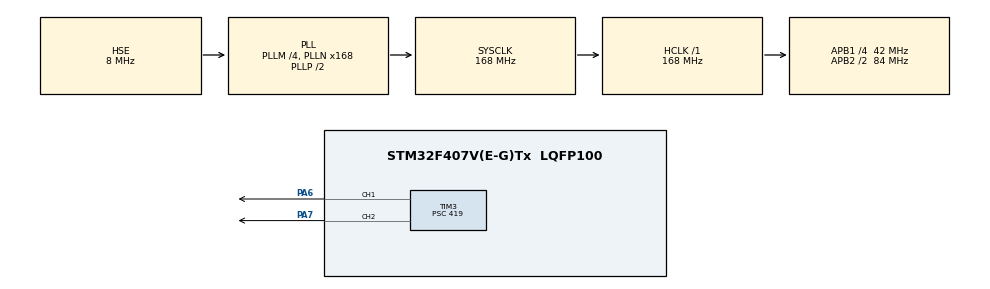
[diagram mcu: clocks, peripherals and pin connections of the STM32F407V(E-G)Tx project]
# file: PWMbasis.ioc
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Mcu.Family=STM32F4
Mcu.Name=STM32F407V(E-G)Tx
Mcu.Package=LQFP100
NVIC.PriorityGroup=NVIC_PRIORITYGROUP_4
PA13.Mode=Serial_Wire
PA13.Signal=SYS_JTMS-SWDIO
PA14.Mode=Serial_Wire
PA14.Signal=SYS_JTCK-SWCLK
PA6.Signal=S_TIM3_CH1
PA7.Signal=S_TIM3_CH2
PH0-OSC_IN.Mode=HSE-External-Oscillator
PH0-OSC_IN.Signal=RCC_OSC_IN
PH1-OSC_OUT.Mode=HSE-External-Oscillator
PH1-OSC_OUT.Signal=RCC_OSC_OUT
ProjectManager.HeapSize=0x200
ProjectManager.StackSize=0x400
ProjectManager.TargetToolchain=STM32CubeIDE
RCC.48MHZClocksFreq_Value=84000000
RCC.AHBFreq_Value=168000000
RCC.APB1CLKDivider=RCC_HCLK_DIV4
RCC.APB1Freq_Value=42000000
RCC.APB1TimFreq_Value=84000000
RCC.APB2CLKDivider=RCC_HCLK_DIV2
RCC.APB2Freq_Value=84000000
RCC.APB2TimFreq_Value=168000000
RCC.CortexFreq_Value=168000000
RCC.HCLKFreq_Value=168000000
RCC.HSE_VALUE=8000000
RCC.HSI_VALUE=16000000
RCC.LSE_VALUE=32768
RCC.PLLM=4
RCC.PLLN=168
RCC.PLLSourceVirtual=RCC_PLLSOURCE_HSE
RCC.SYSCLKFreq_VALUE=168000000
RCC.SYSCLKSource=RCC_SYSCLKSOURCE_PLLCLK
RCC.VCOOutputFreq_Value=336000000
SH.S_TIM3_CH1.0=TIM3_CH1,PWM Generation1 CH1
SH.S_TIM3_CH2.0=TIM3_CH2,PWM Generation2 CH2
TIM3.Channel-PWM\ Generation1\ CH1=TIM_CHANNEL_1
TIM3.Channel-PWM\ Generation2\ CH2=TIM_CHANNEL_2
TIM3.OCMode_PWM-PWM\ Generation1\ CH1=TIM_OCMODE_PWM2
TIM3.OCMode_PWM-PWM\ Generation2\ CH2=TIM_OCMODE_PWM2
TIM3.Prescaler=419
board=custom

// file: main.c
/* USER CODE BEGIN Header */
/**
  ******************************************************************************
  * @file           : main.c
  * @brief          : Main program body
  ******************************************************************************
  * @attention
  *
  * Copyright (c) 2024 STMicroelectronics.
  * All rights reserved.
  *
  * This software is licensed under terms that can be found in the LICENSE file
  * in the root directory of this software component.
  * If no LICENSE file comes with this software, it is provided AS-IS.
  *
  ******************************************************************************
  */
/* USER CODE END Header */
#include "main.h"

TIM_HandleTypeDef htim3;

void SystemClock_Config(void);
static void MX_GPIO_Init(void);
static void MX_TIM3_Init(void);

int main(void)
{

  /* MCU Configuration--------------------------------------------------------*/

  /* Reset of all peripherals, Initializes the Flash interface and the Systick. */
  HAL_Init();

  /* Configure the system clock */
  SystemClock_Config();

  /* Initialize all configured peripherals */
  MX_GPIO_Init();
  MX_TIM3_Init();
  /* USER CODE BEGIN 2 */
  HAL_TIM_PWM_Start(&htim3, TIM_CHANNEL_1); //LED D2 Start timer 3 channel 1
  HAL_TIM_PWM_Start(&htim3, TIM_CHANNEL_2); //LED D2 Start timer 3 channel 1
  __HAL_TIM_SET_AUTORELOAD(&htim3,2000);  //set the pwm freq to 50hz (42Mhz/420)/2000
  /* USER CODE END 2 */

  /* Infinite loop */
  while (1)
  {

    /* USER CODE BEGIN 3 */
	  __HAL_TIM_SET_COMPARE(&htim3, TIM_CHANNEL_1, 200); //LED D2 Set 10% from ARR (2000)

	  HAL_Delay(2000);

	  __HAL_TIM_SET_COMPARE(&htim3, TIM_CHANNEL_1, 600); //LED D2 Set 30% from ARR (2000)

	  HAL_Delay(2000);

	  __HAL_TIM_SET_COMPARE(&htim3, TIM_CHANNEL_1, 1200); //LED D2 Set 60% from ARR (2000)

	  HAL_Delay(2000);

	  __HAL_TIM_SET_COMPARE(&htim3, TIM_CHANNEL_2, 100); //LED D3 Set 5%  from ARR (2000)

	  HAL_Delay(2000);

	  __HAL_TIM_SET_COMPARE(&htim3, TIM_CHANNEL_2, 300); //LED D3 Set 15% from ARR (2000)

	  HAL_Delay(2000);

	  __HAL_TIM_SET_COMPARE(&htim3, TIM_CHANNEL_2, 0); //LED D3 stop

	  HAL_Delay(2000);
  }
  /* USER CODE END 3 */
}

void SystemClock_Config(void)
{
  RCC_OscInitTypeDef RCC_OscInitStruct = {0};
  RCC_ClkInitTypeDef RCC_ClkInitStruct = {0};

  /** Configure the main internal regulator output voltage
  */
  __HAL_RCC_PWR_CLK_ENABLE();
  __HAL_PWR_VOLTAGESCALING_CONFIG(PWR_REGULATOR_VOLTAGE_SCALE1);

  /** Initializes the RCC Oscillators according to the specified parameters
  * in the RCC_OscInitTypeDef structure.
  */
  RCC_OscInitStruct.OscillatorType = RCC_OSCILLATORTYPE_HSE;
  RCC_OscInitStruct.HSEState = RCC_HSE_ON;
  RCC_OscInitStruct.PLL.PLLState = RCC_PLL_ON;
  RCC_OscInitStruct.PLL.PLLSource = RCC_PLLSOURCE_HSE;
  RCC_OscInitStruct.PLL.PLLM = 4;
  RCC_OscInitStruct.PLL.PLLN = 168;
  RCC_OscInitStruct.PLL.PLLP = RCC_PLLP_DIV2;
  RCC_OscInitStruct.PLL.PLLQ = 4;
  if (HAL_RCC_OscConfig(&RCC_OscInitStruct) != HAL_OK)
  {
    Error_Handler();
  }

  /** Initializes the CPU, AHB and APB buses clocks
  */
  RCC_ClkInitStruct.ClockType = RCC_CLOCKTYPE_HCLK|RCC_CLOCKTYPE_SYSCLK
                              |RCC_CLOCKTYPE_PCLK1|RCC_CLOCKTYPE_PCLK2;
  RCC_ClkInitStruct.SYSCLKSource = RCC_SYSCLKSOURCE_PLLCLK;
  RCC_ClkInitStruct.AHBCLKDivider = RCC_SYSCLK_DIV1;
  RCC_ClkInitStruct.APB1CLKDivider = RCC_HCLK_DIV4;
  RCC_ClkInitStruct.APB2CLKDivider = RCC_HCLK_DIV2;

  if (HAL_RCC_ClockConfig(&RCC_ClkInitStruct, FLASH_LATENCY_5) != HAL_OK)
  {
    Error_Handler();
  }
}

static void MX_TIM3_Init(void)
{

  TIM_MasterConfigTypeDef sMasterConfig = {0};
  TIM_OC_InitTypeDef sConfigOC = {0};

  htim3.Instance = TIM3;
  htim3.Init.Prescaler = 419;
  htim3.Init.CounterMode = TIM_COUNTERMODE_UP;
  htim3.Init.Period = 65535;
  htim3.Init.ClockDivision = TIM_CLOCKDIVISION_DIV1;
  htim3.Init.AutoReloadPreload = TIM_AUTORELOAD_PRELOAD_DISABLE;
  if (HAL_TIM_PWM_Init(&htim3) != HAL_OK)
  {
    Error_Handler();
  }
  sMasterConfig.MasterOutputTrigger = TIM_TRGO_RESET;
  sMasterConfig.MasterSlaveMode = TIM_MASTERSLAVEMODE_DISABLE;
  if (HAL_TIMEx_MasterConfigSynchronization(&htim3, &sMasterConfig) != HAL_OK)
  {
    Error_Handler();
  }
  sConfigOC.OCMode = TIM_OCMODE_PWM2;
  sConfigOC.Pulse = 0;
  sConfigOC.OCPolarity = TIM_OCPOLARITY_HIGH;
  sConfigOC.OCFastMode = TIM_OCFAST_DISABLE;
  if (HAL_TIM_PWM_ConfigChannel(&htim3, &sConfigOC, TIM_CHANNEL_1) != HAL_OK)
  {
    Error_Handler();
  }
  if (HAL_TIM_PWM_ConfigChannel(&htim3, &sConfigOC, TIM_CHANNEL_2) != HAL_OK)
  {
    Error_Handler();
  }
  HAL_TIM_MspPostInit(&htim3);

}

static void MX_GPIO_Init(void)
{

  /* GPIO Ports Clock Enable */
  __HAL_RCC_GPIOH_CLK_ENABLE();
  __HAL_RCC_GPIOA_CLK_ENABLE();

}

void Error_Handler(void)
{
  __disable_irq();
  while (1)
  {
  }
}
